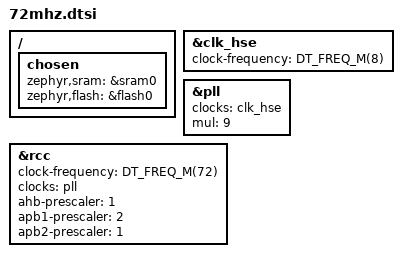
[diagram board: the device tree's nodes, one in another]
/*
 * Copyright (c) 2025 TiaC Systems
 * SPDX-License-Identifier: Apache-2.0
 */

#include <freq.h>

/ {
	chosen {
		zephyr,sram = &sram0;
		zephyr,flash = &flash0;
	};
};

&clk_hse {
	status = "okay";
	clock-frequency = <DT_FREQ_M(8)>;
};

&pll {
	status = "okay";
	clocks = <&clk_hse>;
	mul = <9>;
};

&rcc {
	status = "okay";
	clock-frequency = <DT_FREQ_M(72)>;
	clocks = <&pll>;
	ahb-prescaler = <1>;
	apb1-prescaler = <2>;
	apb2-prescaler = <1>;
	/* usbpre not set: USB clock = 72 / 1.5: 48MHz */
};
